# DIB register map
Vendor: Texas Instruments
Peripheral module from a debugger description file (folder UCD3138R032RJA).
Registers are 32-bit, read-only, reset 0x0 unless marked. A register's access mark holds for its fields unless they carry their own. Offsets are as the file gives them; lines under a group give offsets from that group; [hi:lo] are bit positions; {n}, {i} and the like mark numbered series; 'fields as' and 'values as' point back to an identical list; <NAME> marks a mode.

## DIB
0x00 DLAR — Provides CoreSight discovery information for the SCS
  [0] KEY — Indicates whether Non-secure invasive debug is allowed
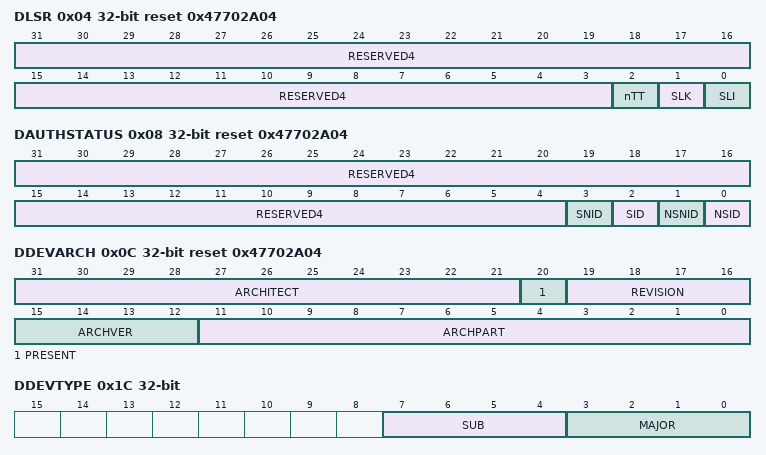
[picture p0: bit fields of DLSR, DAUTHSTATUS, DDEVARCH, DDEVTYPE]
0x04 DLSR reset 0x47702A04 — Provides CoreSight discovery information for the SCS
  [31:3] RESERVED4 — Defines the architect of the component. Bits [31:28] are the JEP106 continuation code (JEP106 bank ID, minus 1) and bits [27:21] are the JEP106 ID code.
  [2] nTT — Indicates whether Secure invasive debug is implemented and allowed
  [1] SLK — Indicates whether Non-secure non-invasive debug is allowed
  [0] SLI — Indicates whether Non-secure invasive debug is allowed
0x08 DAUTHSTATUS reset 0x47702A04 — Provides CoreSight discovery information for the SCS
  [31:4] RESERVED4 — Defines the architect of the component. Bits [31:28] are the JEP106 continuation code (JEP106 bank ID, minus 1) and bits [27:21] are the JEP106 ID code.
  [3] SNID — Indicates whether Secure non-invasive debug is implemented and allowed
  [2] SID — Indicates whether Secure invasive debug is implemented and allowed
  [1] NSNID — Indicates whether Non-secure non-invasive debug is allowed
  [0] NSID — Indicates whether Non-secure invasive debug is allowed
0x0C DDEVARCH reset 0x47702A04 — Provides CoreSight discovery information for the SCS
  [31:21] ARCHITECT — Defines the architect of the component. Bits [31:28] are the JEP106 continuation code (JEP106 bank ID, minus 1) and bits [27:21] are the JEP106 ID code.
  [20] PRESENT — Defines that the DEVARCH register is present
  [19:16] REVISION — Defines the architecture revision of the component
  [15:12] ARCHVER — Defines the architecture version of the component
  [11:0] ARCHPART — Defines the architecture of the component
0x1C DDEVTYPE — Provides CoreSight discovery information for the SCS
  [7:4] SUB — Component sub-type
  [3:0] MAJOR — CoreSight major type
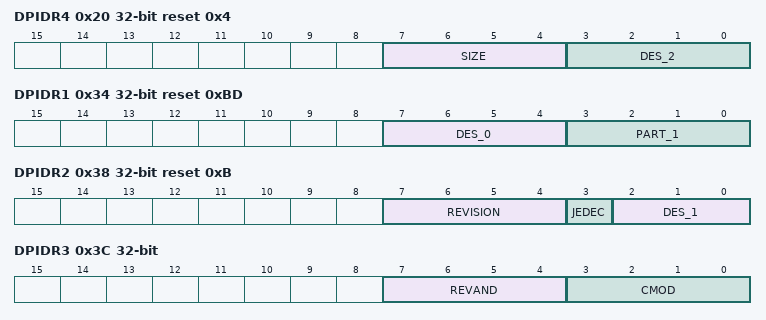
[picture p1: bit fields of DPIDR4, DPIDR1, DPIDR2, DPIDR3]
0x20 DPIDR4 reset 0x4 — Provides CoreSight discovery information for the SCS
  [7:4] SIZE — See CoreSight Architecture Specification
  [3:0] DES_2 — See CoreSight Architecture Specification
{0x10+4i} DPIDR{i} (i=5..7) — Provides CoreSight discovery information for the SCS
0x30 DPIDR0 reset 0x21 — Provides CoreSight discovery information for the SCS
  [7:0] PART_0 — See CoreSight Architecture Specification
0x34 DPIDR1 reset 0xBD — Provides CoreSight discovery information for the SCS
  [7:4] DES_0 — See CoreSight Architecture Specification
  [3:0] PART_1 — See CoreSight Architecture Specification
0x38 DPIDR2 reset 0xB — Provides CoreSight discovery information for the SCS
  [7:4] REVISION — See CoreSight Architecture Specification
  [3] JEDEC — See CoreSight Architecture Specification
  [2:0] DES_1 — See CoreSight Architecture Specification
0x3C DPIDR3 — Provides CoreSight discovery information for the SCS
  [7:4] REVAND — See CoreSight Architecture Specification
  [3:0] CMOD — See CoreSight Architecture Specification
0x40 DCIDR0 reset 0xD — Provides CoreSight discovery information for the SCS
  [7:0] PRMBL_0 — See CoreSight Architecture Specification
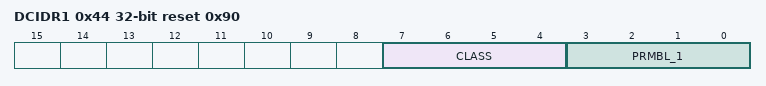
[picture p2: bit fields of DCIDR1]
0x44 DCIDR1 reset 0x90 — Provides CoreSight discovery information for the SCS
  [7:4] CLASS — See CoreSight Architecture Specification
  [3:0] PRMBL_1 — See CoreSight Architecture Specification
0x48 DCIDR2 reset 0x5 — Provides CoreSight discovery information for the SCS
  [7:0] PRMBL_2 — See CoreSight Architecture Specification
0x4C DCIDR3 reset 0xB1 — Provides CoreSight discovery information for the SCS
  [7:0] PRMBL_3 — See CoreSight Architecture Specification
